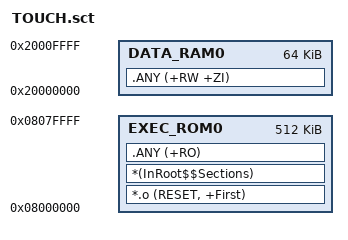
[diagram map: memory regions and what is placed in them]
; *************************************************************
; *** Scatter-Loading Description File generated by TKStudio***
; *************************************************************

LOAD_ROM0 0x08000000   ;Load region
{
EXEC_ROM0 0x08000000 0x00080000  ; load address = execution address
{
   *.o (RESET, +First)
   *(InRoot$$Sections)
   .ANY (+RO)
}
DATA_RAM0 0x20000000  0x00010000  ; RW DATA
{
   .ANY (+RW +ZI)
}
}
